# CM41x_M0 register map
Vendor: Analog Devices; Series: CM41x_M0; File version: 1p0
CPU: CM0 r0p0, little endian, MPU, FPU, 4 interrupt priority bits
Registers are 32-bit, read-write, reset 0x0 unless marked. A register's access mark holds for its fields unless they carry their own. Offsets are from the block's base; [hi:lo] are bit positions; {n}, {i} and the like mark numbered series; 'fields as' and 'values as' point back to an identical list.

## SINC0 — SINC
Base 0x40049000
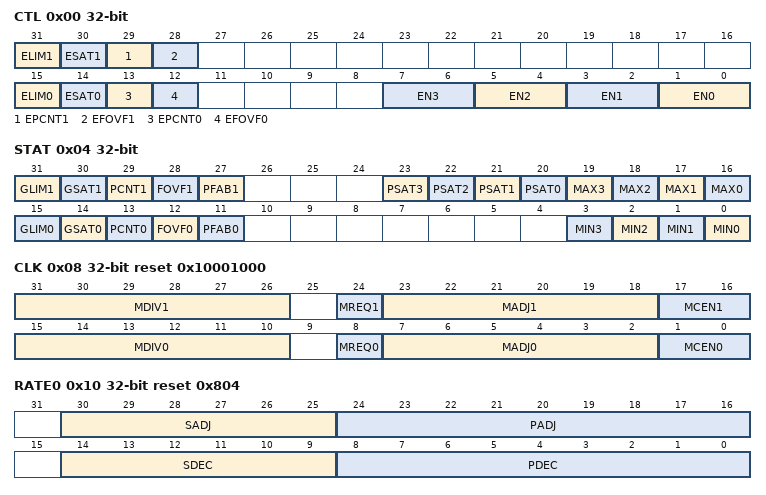
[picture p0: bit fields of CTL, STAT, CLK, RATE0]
0x00 CTL — Control Register
  [31] ELIM1 — Enable Limit for Group 1
  [30] ESAT1 — Enable Saturation for Group 1
  [29] EPCNT1 — Enable Primary Count for Group 1
  [28] EFOVF1 — Enable FIFO Overflow for Group 1
  [15] ELIM0 — Enable Limit for Group 0
  [14] ESAT0 — Enable Saturation for Group 0
  [13] EPCNT0 — Enable Primary Count for Group 0
  [12] EFOVF0 — Enable FIFO Overflow for Group 0
  [2n+1:2n] EN{n} (n=0..3) — Enable Filter Pair {n}
    0=C{n}DIS (Disable); 2=C{n}ENGRP0 (Enable and Assign to Group 0)
0x04 STAT — Status Register
  [31] GLIM1 ro — Group 1 Limit Status
  [30] GSAT1 ro — Group 1 Saturation Status
  [29] PCNT1 — Primary (Filter) Count for Group 1 Status
  [28] FOVF1 — FIFO Overflow for Group 1 Status
  [27] PFAB1 — Primary (Filter) Fabric Error for Group 1 Status
  [n+20] PSAT{n} (n=0..3) — Primary (Filter) {n} Saturation Status
  [n+16] MAX{n} (n=0..3) — Maximum for Secondary Filter {n} Status
  [15] GLIM0 ro — Group 0 Limit Status
  [14] GSAT0 ro — Group 0 Saturation Status
  [13] PCNT0 — Primary (Filter) Count for Group 0 Status
  [12] FOVF0 — FIFO Overflow for Group 0 Status
  [11] PFAB0 — Primary (Filter) Fabric Error for Group 0 Status
  [n] MIN{n} (n=0..3) — Minimum for Secondary Filter {n} Status
0x08 CLK reset 0x10001000 — Clock Control Register
  [31:26] MDIV1 range 0x00000000..0x0000003F — Modulator (Clock) Divider for Group 1
  [24] MREQ1 — Modulator (Clock) Request for Group 1 Status
  [23:18] MADJ1 range 0x00000000..0x0000003F — Modulator (Clock) Adjustment for Group 1
  [17:16] MCEN1 — Modulator (Clock) Enable for Group 1
  [15:10] MDIV0 range 0x00000000..0x0000003F — Modulator (Clock) Divider for Group 0
  [8] MREQ0 — Modulator (Clock) Request for Group 0 Status
  [7:2] MADJ0 range 0x00000000..0x0000003F — Modulator (Clock) Adjustment for Group 0
  [1:0] MCEN0 — Modulator (Clock) Enable for Group 0
0x10 RATE0 reset 0x804 — Rate Control for Group 0 Register
  [30:25] SADJ range 0x00000000..0x0000003F — Secondary (Filter) Adjustment
  [24:16] PADJ range 0x00000000..0x000001FF — Primary (Filter) Adjustment
  [14:9] SDEC range 0x00000000..0x0000003F — Secondary (Filter) Decimation Rate
  [8:0] PDEC range 0x00000000..0x000001FF — Primary (Filter) Decimation Rate
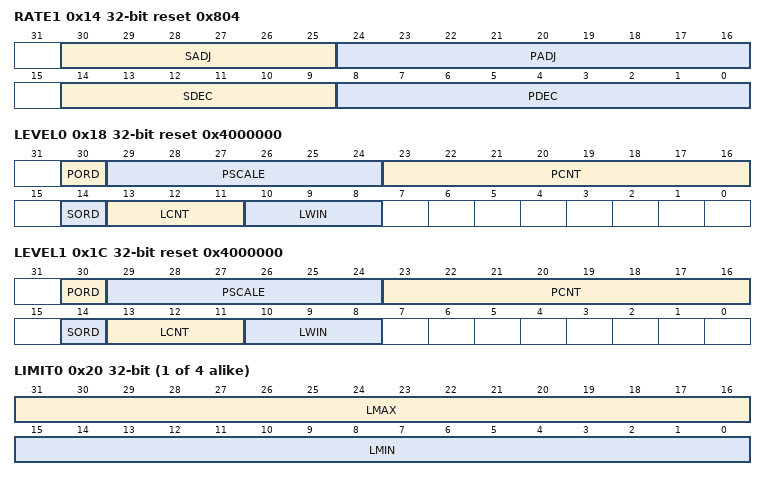
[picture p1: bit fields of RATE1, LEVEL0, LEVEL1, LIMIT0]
0x14 RATE1 reset 0x804 — Rate Control for Group 1 Register
  fields as RATE0
0x18 LEVEL0 reset 0x4000000 — Level Control for Group 0 Register
  [30] PORD — Primary (Filter) Order
  [29:24] PSCALE range 0x00000000..0x0000003F — Primary (Filter) Scaling
  [23:16] PCNT range 0x00000000..0x000000FF — Primary (Filter) Count
  [14] SORD — Secondary (Filter) Order Select
  [13:11] LCNT range 0x00000000..0x00000007 — (Excursion) Limit Count
  [10:8] LWIN range 0x00000000..0x00000007 — (Excursion) Limit Window
0x1C LEVEL1 reset 0x4000000 — Level Control for Group 1 Register
  [30] PORD — Primary (Filter) Order
  [29:24] PSCALE range 0x00000000..0x0000003F — Primary (Filter) Scaling
  [23:16] PCNT range 0x00000000..0x000000FF — Primary (Filter) Count
  [14] SORD — Secondary (Filter) Order
  [13:11] LCNT range 0x00000000..0x00000007 — (Excursion) Limit Count
  [10:8] LWIN range 0x00000000..0x00000007 — (Excursion) Limit Window
{0x20+4i} LIMIT{i} (i=0..3) — (Amplitude) Limits for Secondary Filter {i} Register
  [31:16] LMAX range 0x00000000..0x0000FFFF — Limit Maximum for Secondary Filter {i}
  [15:0] LMIN range 0x00000000..0x0000FFFF — Limit Minimum for Secondary Filter {i}
0x30 BIAS0 — Bias for Group 0 Register
  [31:0] BIAS range 0x00000000..0xFFFFFFFF — Bias for Group 0 Primary Filters
0x34 BIAS1 — Bias for Group 1 Register
  [31:0] BIAS range 0x00000000..0xFFFFFFFF — Bias for Group1 Primary Filters
0x38 PPTR0 — Primary (Filters) Pointer for Group 0 Register
  [31:0] PPTR ro — Primary (Filter) Pointer
0x3C PPTR1 — Primary (Filters) Pointer for Group 1 Register
  [31:0] PPTR ro — Primary (Filter) Pointer
0x40 PHEAD0 — Primary (Filters) Head for Group 0 Register
  [31:1] PHEAD range 0x00000000..0x7FFFFFFF — Primary (Filter) Head Pointer
0x44 PHEAD1 — Primary (Filters) Head for Group 1 Register
  fields as PHEAD0
0x48 PTAIL0 — Primary (Filters) Tail for Group 0 Register
  [31:1] PTAIL range 0x00000000..0x7FFFFFFF — Primary (Filter) Tail Pointer
0x4C PTAIL1 — Primary (Filters) Tail for Group 1 Register
  fields as PTAIL0
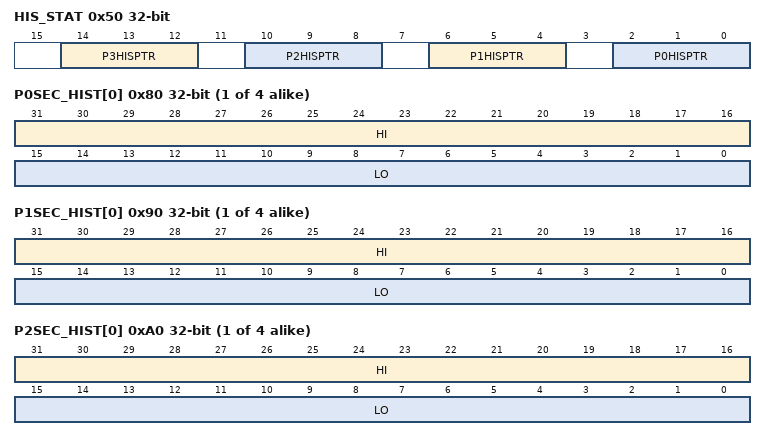
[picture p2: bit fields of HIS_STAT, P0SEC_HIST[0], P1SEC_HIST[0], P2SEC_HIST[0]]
0x50 HIS_STAT — History Status Register
  [14:12] P3HISPTR ro — Pair 3 History Pointer
    0=P3HIS0_H (History Register 3, MS); 1=P3HIS1_L (History Register 0, LS); 2=P3HIS1_H (History Register 0, MS); 3=P3HIS2_L (History Register 1, LS); 4=P3HIS2_H (History Register 1, MS); 5=P3HIS3_L (History Register 2, LS); 6=P3HIS3_H (History Register 2, MS); 7=P3HIS0_L (History Register 3, LS)
  [10:8] P2HISPTR ro — Pair 2 History Pointer
    0=P2HIS0_H (History Register 3, MS); 1=P2HIS1_L (History Register 0, LS); 2=P2HIS1_H (History Register 0, MS); 3=P2HIS2_L (History Register 1, LS); 4=P2HIS2_H (History Register 1, MS); 5=P2HIS3_L (History Register 2, LS); 6=P2HIS3_H (History Register 2, MS); 7=P2HIS0_L (History Register 3, LS)
  [6:4] P1HISPTR ro — Pair 1 History Pointer
    0=P1HIS0_H (History Register 3, MS); 1=P1HIS1_L (History Register, LS); 2=P1HIS1_H (History Register 0, MS); 3=P1HIS2_L (History Register 1, LS); 4=P1HIS2_H (History Register 1, MS); 5=P1HIS3_L (History Register 2, LS); 6=P1HIS3_H (History Register 2, MS); 7=P1HIS0_L (History Register 3, LS)
  [2:0] P0HISPTR ro — Pair 0 History Pointer
    0=P0HIS0_H (History Register 3, MS); 1=P0HIS1_L (History Register 0, LS); 2=P0HIS1_H (History Register 0, MS); 3=P0HIS2_L (History Register 1, LS); 4=P0HIS2_H (History Register 1, MS); 5=P0HIS3_L (History Register 2, LS); 6=P0HIS3_H (History Register 2, MS); 7=P0HIS0_L (History Register 3, LS)
{0x80+4i} P0SEC_HIST[{i}] (i=0..3) — Pair 0 Secondary (Filter) History n Register
  [31:16] HI ro — High Data Word
  [15:0] LO ro — Low Data Word
{0x90+4i} P1SEC_HIST[{i}] (i=0..3) — Pair 1 Secondary (Filter) History n Register
  [31:16] HI ro — High Data Word
  [15:0] LO ro — Low Data Word
{0xA0+4i} P2SEC_HIST[{i}] (i=0..3) — Pair 2 Secondary (Filter) History n Register
  [31:16] HI ro — High Data Word
  [15:0] LO ro — Low Data Word
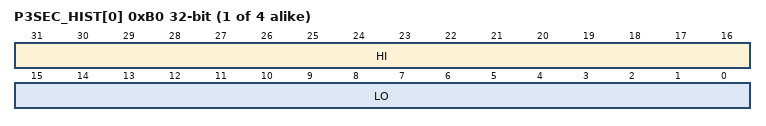
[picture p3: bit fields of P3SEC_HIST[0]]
{0xB0+4i} P3SEC_HIST[{i}] (i=0..3) — Pair 3 Secondary (Filter) History n Register
  [31:16] HI ro — High Data Word
  [15:0] LO ro — Low Data Word
